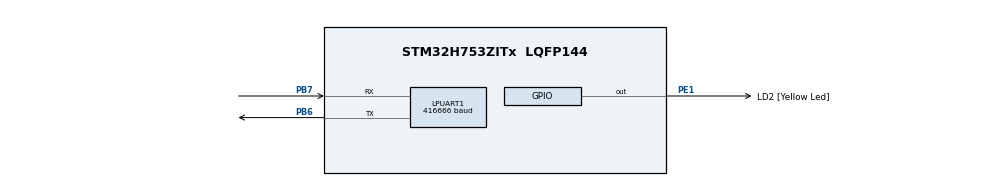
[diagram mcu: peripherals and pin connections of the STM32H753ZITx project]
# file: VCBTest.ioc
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Bdma.LPUART1_RX.0.Direction=DMA_PERIPH_TO_MEMORY
Bdma.LPUART1_RX.0.EventEnable=DISABLE
Bdma.LPUART1_RX.0.Instance=BDMA_Channel0
Bdma.LPUART1_RX.0.MemDataAlignment=DMA_MDATAALIGN_BYTE
Bdma.LPUART1_RX.0.MemInc=DMA_MINC_ENABLE
Bdma.LPUART1_RX.0.Mode=DMA_NORMAL
Bdma.LPUART1_RX.0.PeriphDataAlignment=DMA_PDATAALIGN_BYTE
Bdma.LPUART1_RX.0.PeriphInc=DMA_PINC_DISABLE
Bdma.LPUART1_RX.0.Polarity=HAL_DMAMUX_REQ_GEN_RISING
Bdma.LPUART1_RX.0.Priority=DMA_PRIORITY_HIGH
Bdma.LPUART1_RX.0.RequestNumber=1
Bdma.LPUART1_RX.0.SignalID=NONE
Bdma.LPUART1_RX.0.SyncEnable=DISABLE
Bdma.LPUART1_RX.0.SyncPolarity=HAL_DMAMUX_SYNC_NO_EVENT
Bdma.LPUART1_RX.0.SyncRequestNumber=1
Bdma.LPUART1_RX.0.SyncSignalID=NONE
Bdma.Request0=LPUART1_RX
Bdma.RequestsNb=1
CORTEX_M7.CPU_DCache=Disabled
CORTEX_M7.CPU_ICache=Disabled
CORTEX_M7.MPU_Control=__NULL
CORTEX_M7.default_mode_Activation=1
LPUART1.BaudRate=416666
Mcu.Family=STM32H7
Mcu.Name=STM32H753ZITx
Mcu.Package=LQFP144
NUCLEO-H753ZI.BUTTON=0
NUCLEO-H753ZI.LD1=false
NUCLEO-H753ZI.LD2=false
NUCLEO-H753ZI.LD3=false
NUCLEO-H753ZI.VCP=true
NVIC.BDMA_Channel0_IRQn=true\:0\:0\:false\:false\:true\:false\:true\:true
NVIC.LPUART1_IRQn=true\:0\:0\:false\:false\:true\:true\:true\:true
NVIC.PriorityGroup=NVIC_PRIORITYGROUP_4
PB6.Mode=Asynchronous
PB6.Signal=LPUART1_TX
PB7.Mode=Asynchronous
PB7.Signal=LPUART1_RX
PC14-OSC32_IN\ (OSC32_IN).Signal=RCC_OSC32_IN
PC15-OSC32_OUT\ (OSC32_OUT).Signal=RCC_OSC32_OUT
PD8.Signal=USART3_TX
PD9.Signal=USART3_RX
PE1.GPIO_Label=LD2 [Yellow Led]
PE1.Signal=GPIO_Output
PH0-OSC_IN\ (PH0).Signal=RCC_OSC_IN
PH1-OSC_OUT\ (PH1).Signal=RCC_OSC_OUT
ProjectManager.HeapSize=0x200
ProjectManager.StackSize=0x400
ProjectManager.TargetToolchain=STM32CubeIDE
RCC.ADCFreq_Value=120000000
RCC.APB1Freq_Value=120000000
RCC.APB2Freq_Value=120000000
RCC.APB3Freq_Value=120000000
RCC.APB4Freq_Value=120000000
RCC.CortexFreq_Value=120000000
RCC.DIVM1=8
RCC.DIVM2=8
RCC.DIVM3=8
RCC.DIVN1=30
RCC.DIVN2=30
RCC.DIVN3=30
RCC.DIVQ1=4
RCC.DIVQ2=4
RCC.HCLKFreq_Value=120000000
RCC.HSE_VALUE=8000000
RCC.LPUART1CLockSelection=RCC_LPUART1CLKSOURCE_PLL2
RCC.PLLFRACN=0
RCC.PWR_Regulator_Voltage_Scale=PWR_REGULATOR_VOLTAGE_SCALE2
RCC.SYSCLKFreq_VALUE=120000000
RCC.SYSCLKSource=RCC_SYSCLKSOURCE_PLLCLK
RCC.USBFreq_Value=60000000
VP_MEMORYMAP_VS_MEMORYMAP.Mode=CurAppReg
VP_NUCLEO-H753ZI_VS_BSP_COMMON.Mode=COMMON
board=NUCLEO-H753ZI

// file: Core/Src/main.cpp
/* USER CODE BEGIN Header */
/**
  ******************************************************************************
  * @file           : main.c
  * @brief          : Main program body
  ******************************************************************************
  * @attention
  *
  * Copyright (c) 2026 STMicroelectronics.
  * All rights reserved.
  *
  * This software is licensed under terms that can be found in the LICENSE file
  * in the root directory of this software component.
  * If no LICENSE file comes with this software, it is provided AS-IS.
  *
  ******************************************************************************
  */
/* USER CODE END Header */
#include "main.h"

/* USER CODE BEGIN Includes */
#include "crsf.h"
/* USER CODE END Includes */

/* USER CODE BEGIN PM */
#if defined( __ICCARM__ )
  #define DMA_BUFFER \
      _Pragma("location=\".dma_buffer\"")
#else
  #define DMA_BUFFER \
      __attribute__((section(".dma_buffer")))
#endif
/* USER CODE END PM */

COM_InitTypeDef BspCOMInit;

UART_HandleTypeDef hlpuart1;
DMA_HandleTypeDef hdma_lpuart1_rx;

/* USER CODE BEGIN PV */
// DMA_BUFFER uint8_t rxBuffer[256] = {0};
CRSF crsf;
/* USER CODE END PV */

void SystemClock_Config(void);
static void MX_GPIO_Init(void);
static void MX_BDMA_Init(void);
static void MX_LPUART1_UART_Init(void);

int main(void)
{

  /* MCU Configuration--------------------------------------------------------*/

  /* Reset of all peripherals, Initializes the Flash interface and the Systick. */
  HAL_Init();

  /* Configure the system clock */
  SystemClock_Config();

  /* Initialize all configured peripherals */
  MX_GPIO_Init();
  MX_BDMA_Init();
  MX_LPUART1_UART_Init();
  /* USER CODE BEGIN 2 */
  // Initialize CRSF with the UART handle
  crsf.init(&hlpuart1);

  // // Start DMA reception
  // HAL_UARTEx_ReceiveToIdle_DMA(&hlpuart1, crsf.rxData, sizeof(crsf.rxData));

  /* USER CODE END 2 */

  /* Initialize COM1 port (115200, 8 bits (7-bit data + 1 stop bit), no parity */
  BspCOMInit.BaudRate   = 115200;
  BspCOMInit.WordLength = COM_WORDLENGTH_8B;
  BspCOMInit.StopBits   = COM_STOPBITS_1;
  BspCOMInit.Parity     = COM_PARITY_NONE;
  BspCOMInit.HwFlowCtl  = COM_HWCONTROL_NONE;
  if (BSP_COM_Init(COM1, &BspCOMInit) != BSP_ERROR_NONE)
  {
    Error_Handler();
  }

  /* Infinite loop */
  /* USER CODE BEGIN WHILE */
  while (1)
  {
    HAL_Delay(20);
    // crsf.printLatestPacket();
    crsf.parseLatestPacket();
    /* USER CODE END WHILE */

  }
}

void SystemClock_Config(void)
{
  RCC_OscInitTypeDef RCC_OscInitStruct = {0};
  RCC_ClkInitTypeDef RCC_ClkInitStruct = {0};

  /** Supply configuration update enable
  */
  HAL_PWREx_ConfigSupply(PWR_LDO_SUPPLY);

  /** Configure the main internal regulator output voltage
  */
  __HAL_PWR_VOLTAGESCALING_CONFIG(PWR_REGULATOR_VOLTAGE_SCALE2);

  while(!__HAL_PWR_GET_FLAG(PWR_FLAG_VOSRDY)) {}

  /** Initializes the RCC Oscillators according to the specified parameters
  * in the RCC_OscInitTypeDef structure.
  */
  RCC_OscInitStruct.OscillatorType = RCC_OSCILLATORTYPE_HSI;
  RCC_OscInitStruct.HSIState = RCC_HSI_DIV1;
  RCC_OscInitStruct.HSICalibrationValue = RCC_HSICALIBRATION_DEFAULT;
  RCC_OscInitStruct.PLL.PLLState = RCC_PLL_ON;
  RCC_OscInitStruct.PLL.PLLSource = RCC_PLLSOURCE_HSI;
  RCC_OscInitStruct.PLL.PLLM = 8;
  RCC_OscInitStruct.PLL.PLLN = 30;
  RCC_OscInitStruct.PLL.PLLP = 2;
  RCC_OscInitStruct.PLL.PLLQ = 4;
  RCC_OscInitStruct.PLL.PLLR = 2;
  RCC_OscInitStruct.PLL.PLLRGE = RCC_PLL1VCIRANGE_3;
  RCC_OscInitStruct.PLL.PLLVCOSEL = RCC_PLL1VCOWIDE;
  RCC_OscInitStruct.PLL.PLLFRACN = 0;
  if (HAL_RCC_OscConfig(&RCC_OscInitStruct) != HAL_OK)
  {
    Error_Handler();
  }

  /** Initializes the CPU, AHB and APB buses clocks
  */
  RCC_ClkInitStruct.ClockType = RCC_CLOCKTYPE_HCLK|RCC_CLOCKTYPE_SYSCLK
                              |RCC_CLOCKTYPE_PCLK1|RCC_CLOCKTYPE_PCLK2
                              |RCC_CLOCKTYPE_D3PCLK1|RCC_CLOCKTYPE_D1PCLK1;
  RCC_ClkInitStruct.SYSCLKSource = RCC_SYSCLKSOURCE_PLLCLK;
  RCC_ClkInitStruct.SYSCLKDivider = RCC_SYSCLK_DIV1;
  RCC_ClkInitStruct.AHBCLKDivider = RCC_HCLK_DIV1;
  RCC_ClkInitStruct.APB3CLKDivider = RCC_APB3_DIV1;
  RCC_ClkInitStruct.APB1CLKDivider = RCC_APB1_DIV1;
  RCC_ClkInitStruct.APB2CLKDivider = RCC_APB2_DIV1;
  RCC_ClkInitStruct.APB4CLKDivider = RCC_APB4_DIV1;

  if (HAL_RCC_ClockConfig(&RCC_ClkInitStruct, FLASH_LATENCY_2) != HAL_OK)
  {
    Error_Handler();
  }
}

static void MX_LPUART1_UART_Init(void)
{

  hlpuart1.Instance = LPUART1;
  hlpuart1.Init.BaudRate = 416666;
  hlpuart1.Init.WordLength = UART_WORDLENGTH_8B;
  hlpuart1.Init.StopBits = UART_STOPBITS_1;
  hlpuart1.Init.Parity = UART_PARITY_NONE;
  hlpuart1.Init.Mode = UART_MODE_TX_RX;
  hlpuart1.Init.HwFlowCtl = UART_HWCONTROL_NONE;
  hlpuart1.Init.OneBitSampling = UART_ONE_BIT_SAMPLE_DISABLE;
  hlpuart1.Init.ClockPrescaler = UART_PRESCALER_DIV1;
  hlpuart1.AdvancedInit.AdvFeatureInit = UART_ADVFEATURE_NO_INIT;
  hlpuart1.FifoMode = UART_FIFOMODE_DISABLE;
  if (HAL_UART_Init(&hlpuart1) != HAL_OK)
  {
    Error_Handler();
  }
  if (HAL_UARTEx_SetTxFifoThreshold(&hlpuart1, UART_TXFIFO_THRESHOLD_1_8) != HAL_OK)
  {
    Error_Handler();
  }
  if (HAL_UARTEx_SetRxFifoThreshold(&hlpuart1, UART_RXFIFO_THRESHOLD_1_8) != HAL_OK)
  {
    Error_Handler();
  }
  if (HAL_UARTEx_DisableFifoMode(&hlpuart1) != HAL_OK)
  {
    Error_Handler();
  }

}

static void MX_BDMA_Init(void)
{

  /* DMA controller clock enable */
  __HAL_RCC_BDMA_CLK_ENABLE();

  /* DMA interrupt init */
  /* BDMA_Channel0_IRQn interrupt configuration */
  HAL_NVIC_SetPriority(BDMA_Channel0_IRQn, 0, 0);
  HAL_NVIC_EnableIRQ(BDMA_Channel0_IRQn);

}

static void MX_GPIO_Init(void)
{
  GPIO_InitTypeDef GPIO_InitStruct = {0};

  /* GPIO Ports Clock Enable */
  __HAL_RCC_GPIOC_CLK_ENABLE();
  __HAL_RCC_GPIOH_CLK_ENABLE();
  __HAL_RCC_GPIOB_CLK_ENABLE();
  __HAL_RCC_GPIOE_CLK_ENABLE();

  /*Configure GPIO pin Output Level */
  HAL_GPIO_WritePin(LD2_GPIO_Port, LD2_Pin, GPIO_PIN_RESET);

  /*Configure GPIO pin : LD2_Pin */
  GPIO_InitStruct.Pin = LD2_Pin;
  GPIO_InitStruct.Mode = GPIO_MODE_OUTPUT_PP;
  GPIO_InitStruct.Pull = GPIO_NOPULL;
  GPIO_InitStruct.Speed = GPIO_SPEED_FREQ_LOW;
  HAL_GPIO_Init(LD2_GPIO_Port, &GPIO_InitStruct);

}

/* USER CODE BEGIN 4 */
void HAL_UARTEx_RxEventCallback(UART_HandleTypeDef *huart, uint16_t Size) {
  // Process received data and reset DMA for next reception
  crsf.processReceivedData(huart, Size);
}

void HAL_UART_ErrorCallback(UART_HandleTypeDef *huart) {
  // Handle UART errors and reset DMA for next reception
  crsf.overrunErrorHandler(huart);
}
/* USER CODE END 4 */

void Error_Handler(void)
{
  __disable_irq();
  while (1)
  {
  }
}
